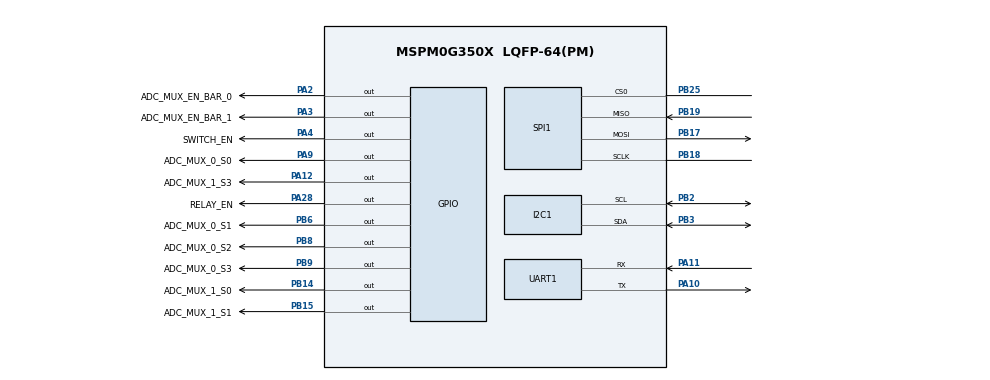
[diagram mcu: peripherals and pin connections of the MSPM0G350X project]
/**
 * @cliArgs --device "MSPM0G350X" --part "Default" --package "LQFP-64(PM)" --product "mspm0_sdk@2.10.00.04"
 * @versions {"tool":"1.26.2+4477"}
 */

/**
 * Import the modules used in this configuration.
 */
const GPIO   = scripting.addModule("/ti/driverlib/GPIO", {}, false);
const GPIO1  = GPIO.addInstance();
const GPIO2  = GPIO.addInstance();
const GPIO3  = GPIO.addInstance();
const GPIO4  = GPIO.addInstance();
const GPIO5  = GPIO.addInstance();
const I2C    = scripting.addModule("/ti/driverlib/I2C", {}, false);
const I2C1   = I2C.addInstance();
const SPI    = scripting.addModule("/ti/driverlib/SPI", {}, false);
const SPI1   = SPI.addInstance();
const SYSCTL = scripting.addModule("/ti/driverlib/SYSCTL");
const TIMER  = scripting.addModule("/ti/driverlib/TIMER", {}, false);
const TIMER1 = TIMER.addInstance();
const TIMER2 = TIMER.addInstance();
const UART   = scripting.addModule("/ti/driverlib/UART", {}, false);
const UART1  = UART.addInstance();

/**
 * Write custom configuration values to the imported modules.
 */
GPIO1.$name                          = "ADC_MUX_EN";
GPIO1.associatedPins.create(2);
GPIO1.associatedPins[0].$name        = "ADC_MUX_EN_BAR_0";
GPIO1.associatedPins[0].initialValue = "SET";
GPIO1.associatedPins[0].pin.$assign  = "PA2";
GPIO1.associatedPins[1].$name        = "ADC_MUX_EN_BAR_1";
GPIO1.associatedPins[1].initialValue = "SET";
GPIO1.associatedPins[1].pin.$assign  = "PA3";

const Board = scripting.addModule("/ti/driverlib/Board", {}, false);

GPIO2.$name                         = "RELAY";
GPIO2.associatedPins[0].$name       = "RELAY_EN";
GPIO2.associatedPins[0].pin.$assign = "PA28";

GPIO3.$name                         = "SWITCH";
GPIO3.associatedPins[0].$name       = "SWITCH_EN";
GPIO3.associatedPins[0].pin.$assign = "PA4";

GPIO4.$name                         = "ADC_MUX_0";
GPIO4.associatedPins.create(4);
GPIO4.associatedPins[0].$name       = "ADC_MUX_0_S0";
GPIO4.associatedPins[0].pin.$assign = "PA9";
GPIO4.associatedPins[1].$name       = "ADC_MUX_0_S1";
GPIO4.associatedPins[1].pin.$assign = "PB6";
GPIO4.associatedPins[2].$name       = "ADC_MUX_0_S2";
GPIO4.associatedPins[2].pin.$assign = "PB8";
GPIO4.associatedPins[3].$name       = "ADC_MUX_0_S3";
GPIO4.associatedPins[3].pin.$assign = "PB9";

GPIO5.$name                         = "ADC_MUX_1";
GPIO5.associatedPins.create(4);
GPIO5.associatedPins[0].$name       = "ADC_MUX_1_S0";
GPIO5.associatedPins[0].pin.$assign = "PB14";
GPIO5.associatedPins[1].$name       = "ADC_MUX_1_S1";
GPIO5.associatedPins[1].pin.$assign = "PB15";
GPIO5.associatedPins[2].$name       = "ADC_MUX_1_S2";
GPIO5.associatedPins[3].$name       = "ADC_MUX_1_S3";
GPIO5.associatedPins[3].pin.$assign = "PA12";

I2C1.$name                             = "MCU_I2C";
I2C1.basicEnableController             = true;
I2C1.peripheral.$assign                = "I2C1";
I2C1.peripheral.sdaPin.$assign         = "PB3";
I2C1.peripheral.sclPin.$assign         = "PB2";
I2C1.sdaPinConfig.$name                = "ti_driverlib_gpio_GPIOPinGeneric2";
I2C1.sdaPinConfig.hideOutputInversion  = scripting.forceWrite(false);
I2C1.sdaPinConfig.onlyInternalResistor = scripting.forceWrite(false);
I2C1.sdaPinConfig.passedPeripheralType = scripting.forceWrite("Digital");
I2C1.sclPinConfig.$name                = "ti_driverlib_gpio_GPIOPinGeneric3";
I2C1.sclPinConfig.hideOutputInversion  = scripting.forceWrite(false);
I2C1.sclPinConfig.onlyInternalResistor = scripting.forceWrite(false);
I2C1.sclPinConfig.passedPeripheralType = scripting.forceWrite("Digital");

SPI1.$name                      = "SPI_0";
SPI1.targetBitRate              = 1000000;
SPI1.dataSize                   = 16;
SPI1.enabledInterrupts          = ["IDLE","RX","RX_FULL","RX_OVERFLOW","RX_TIMEOUT","TX","TX_UNDERFLOW"];
SPI1.peripheral.sclkPin.$assign = "PB18";
SPI1.peripheral.mosiPin.$assign = "PB17";
SPI1.peripheral.misoPin.$assign = "PB19";
SPI1.peripheral.cs0Pin.$assign  = "PB25";
SPI1.sclkPinConfig.$name        = "ti_driverlib_gpio_GPIOPinGeneric4";
SPI1.mosiPinConfig.$name        = "ti_driverlib_gpio_GPIOPinGeneric5";
SPI1.misoPinConfig.$name        = "ti_driverlib_gpio_GPIOPinGeneric6";
SPI1.cs0PinConfig.$name         = "ti_driverlib_gpio_GPIOPinGeneric7";

SYSCTL.forceDefaultClkConfig = true;

TIMER1.$name              = "TIMER_0";
TIMER1.timerMode          = "ONE_SHOT_UP";
TIMER1.interrupts         = ["LOAD"];
TIMER1.peripheral.$assign = "TIMA0";

TIMER2.$name              = "TIMER_1";
TIMER2.timerClkPrescale   = 32;
TIMER2.timerMode          = "PERIODIC_UP";
TIMER2.interrupts         = ["ZERO"];
TIMER2.peripheral.$assign = "TIMG0";

UART1.$name                    = "UART_0";
UART1.targetBaudRate           = 115200;
UART1.enabledInterrupts        = ["EOT_DONE","RX","RXD_NEG_EDGE","RXD_POS_EDGE","TX"];
UART1.peripheral.rxPin.$assign = "PA11";
UART1.peripheral.txPin.$assign = "PA10";
UART1.txPinConfig.$name        = "ti_driverlib_gpio_GPIOPinGeneric0";
UART1.rxPinConfig.$name        = "ti_driverlib_gpio_GPIOPinGeneric1";

/**
 * Pinmux solution for unlocked pins/peripherals. This ensures that minor changes to the automatic solver in a future
 * version of the tool will not impact the pinmux you originally saw.  These lines can be completely deleted in order to
 * re-solve from scratch.
 */
Board.peripheral.$suggestSolution            = "DEBUGSS";
Board.peripheral.swclkPin.$suggestSolution   = "PA20";
Board.peripheral.swdioPin.$suggestSolution   = "PA19";
GPIO5.associatedPins[2].pin.$suggestSolution = "PB13";
SPI1.peripheral.$suggestSolution             = "SPI0";
SYSCTL.peripheral.$suggestSolution           = "SYSCTL";
UART1.peripheral.$suggestSolution            = "UART0";
